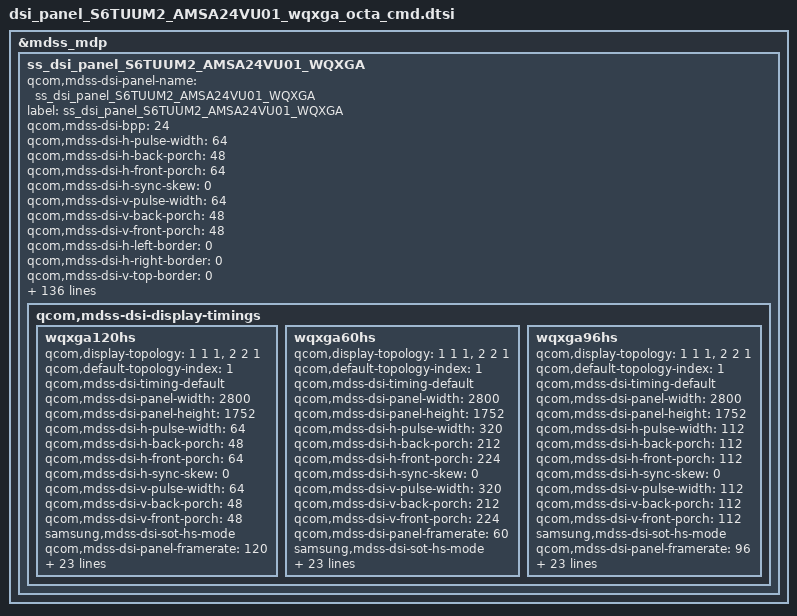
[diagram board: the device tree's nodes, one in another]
/* Copyright (c) 2012, Samsung Electronics Corporation. All rights reserved.
 *
 * This program is free software; you can redistribute it and/or modify
 * it under the terms of the GNU General Public License version 2 and
 * only version 2 as published by the Free Software Foundation.
 *
 * This program is distributed in the hope that it will be useful,
 * but WITHOUT ANY WARRANTY; without even the implied warranty of
 * MERCHANTABILITY or FITNESS FOR A PARTICULAR PURPOSE.  See the
 * GNU General Public License for more details.
 */

&mdss_mdp {
	ss_dsi_panel_S6TUUM2_AMSA24VU01_WQXGA: ss_dsi_panel_S6TUUM2_AMSA24VU01_WQXGA {
		qcom,mdss-dsi-panel-name = "ss_dsi_panel_S6TUUM2_AMSA24VU01_WQXGA";
		label = "ss_dsi_panel_S6TUUM2_AMSA24VU01_WQXGA";

		qcom,mdss-dsi-bpp = <24>;

		/*qcom,cmd-sync-wait-broadcast;*/

		/* 120Hz */
		qcom,mdss-dsi-h-pulse-width = < 64>;
		qcom,mdss-dsi-h-back-porch = <48>;
		qcom,mdss-dsi-h-front-porch = <64>;
		qcom,mdss-dsi-h-sync-skew = <0>;

		qcom,mdss-dsi-v-pulse-width = <64>;
		qcom,mdss-dsi-v-back-porch = <48>;
		qcom,mdss-dsi-v-front-porch = <48>;

		qcom,mdss-dsi-h-left-border = <0>;
		qcom,mdss-dsi-h-right-border = <0>;
		qcom,mdss-dsi-v-top-border = <0>;
		qcom,mdss-dsi-v-bottom-border = <0>;

		qcom,mdss-dsi-underflow-color = <0xFF>;
		qcom,mdss-dsi-border-color = <0>;

		qcom,mdss-dsi-panel-framerate = <120>;
		//qcom,mdss-dsi-panel-clockrate = <1530000000>;
		qcom,mdss-dsi-panel-phy-timings = [00 31 0D 0D 2B 27 0D 0D 09 02 04 00 27 1C];
		qcom,mdss-dsi-t-clk-pre = <0x27>;
		qcom,mdss-dsi-t-clk-post = <0x1C>;

		qcom,mdss-dsi-bl-pmic-control-type = "bl_ctrl_dcs";

		qcom,mdss-dsi-bl-min-level = <1>;
		qcom,mdss-dsi-bl-max-level = <355>;
		qcom,mdss-brightness-max-level = <355>;
		qcom,mdss-brightness-default-level = <255>;
		qcom,mdss-dsi-interleave-mode = <0>;
		qcom,mdss-dsi-panel-type = "dsi_cmd_mode";

		qcom,mdss-dsi-te-check-enable;
		qcom,mdss-dsi-te-using-te-pin;
		qcom,mdss-dsi-te-pin-select = <1>;

		/*qcom,dynamic-mode-switch-enabled;*/
		/*qcom,dynamic-mode-switch-type = "dynamic-resolution-switch-immediate";*/

		qcom,mdss-dsi-te-dcs-command = <1>;
		qcom,mdss-dsi-wr-mem-start = <0x2C>;
		qcom,mdss-dsi-wr-mem-continue = <0x3C>;

		qcom,mdss-dsi-pixel-packing = "loose";

		qcom,mdss-dsi-virtual-channel-id = <0>;
		qcom,mdss-dsi-color-order = "rgb_swap_rgb";
		qcom,mdss-dsi-lane-0-state;
		qcom,mdss-dsi-lane-1-state;
		qcom,mdss-dsi-lane-2-state;
		qcom,mdss-dsi-lane-3-state;
		qcom,mdss-dsi-lane-map = "lane_map_0123";
		samsung,num_of_data_lanes = <4>;

		qcom,mdss-dsi-stream = <0>;
		qcom,mdss-dsi-mdp-trigger = "none";
		qcom,mdss-dsi-dma-trigger = "trigger_sw";

		qcom,mdss-pan-physical-width-dimension = <272>; /* 272.82, round off */
		qcom,mdss-pan-physical-height-dimension = <175>; /* 175.0608, round off */

		qcom,mdss-dsi-reset-sequence = <0 1>, <1 1>;

		/*qcom,mdss-dsi-lp11-init;*/
		/*qcom,mdss-dsi-init-delay-us = <1000>;*/
		/*samsung,mdss-dsi-off-reset-delay-us = <1000>;*/

		qcom,mdss-dsi-rx-eot-ignore;
		qcom,mdss-dsi-tx-eot-append;

		/* HDR Setting */
		qcom,mdss-dsi-panel-hdr-enabled;
		qcom,mdss-dsi-panel-hdr-color-primaries = <15635 16450 34000 16000 13250 34500 7500 3000>;
		qcom,mdss-dsi-panel-peak-brightness = <5400000>;
		qcom,mdss-dsi-panel-average-brightness = <2000000>;
		qcom,mdss-dsi-panel-blackness-level = <2000>;

		qcom,ulps-enabled;
		/* qcom,suspend-ulps-enabled; */
		qcom,esd-check-enabled;
		qcom,mdss-dsi-panel-status-check-mode ="irq_check";
		/*qcom,mdss-dsi-panel-status-read-length;*/
		/*qcom,mdss-dsi-panel-status-value;*/
		/*qcom,mdss-dsi-panel-status-irq-trigger1 = "rising";*/
		qcom,mdss-dsi-panel-status-irq-trigger1 = "falling";

		/* *************************************************************
		 * Below  parameters are samsung dependent thigs
		 * *************************************************************
		 */
		samsung,panel-vendor = "SDC";
		samsung,disp-model = "AMSA24VU01";
		/*samsung,tcon-clk-on-support;*/ /* Enable only if HS clock is needed always like ANA */
		samsung,anapass-power-seq;
		samsung,delay-after-tcon-ready = <50>;  //PV1:100ms, PV2:50ms
		//samsung,panel-lpm-enable;
		samsung,esc-clk-128M;
		samsung,support_gamma_mode2;
		//samsung,elvss_interpolation_temperature = <(-15)>;
		//samsung,support_factory_panel_swap;
		//samsung,support_gct;
		//samsung,support_pac;
		//samsung,support_gpara; 2byte G-para
		// samsung,support_poc_driver;
		samsung,support_dynamic_mipi_clk;
		samsung,pll_ssc_disabled;
		samsung,no_qcom_pps;

		samsung,support-optical-fingerprint;
		samsung,not-support-single-tx; /* Do not support single tx */

		/* *************************************************************
		 *  Tx
		 * *************************************************************
		 */
		//samsung,level0_key_enable_tx_cmds_revA	= [29 01 00 00 00 00 03 9F A5 A5]; /* PASSWD0 */
		//samsung,level0_key_disable_tx_cmds_revA	= [29 01 00 00 00 00 03 9F 5A 5A]; /* PASSWD0 */
		//samsung,level1_key_enable_tx_cmds_revA	= [29 01 00 00 00 00 03 F0 5A 5A]; /* PASSWD1 */
		//samsung,level1_key_disable_tx_cmds_revA	= [29 01 00 00 00 00 03 F0 A5 A5]; /* PASSWD1 */
		//samsung,level2_key_enable_tx_cmds_revA	= [29 01 00 00 00 00 03 FC 5A 5A];
		//samsung,level2_key_disable_tx_cmds_revA	= [29 01 00 00 00 00 03 FC A5 A5];

		/* BRIGHTNESS_MAX_PACKET = 50 */
		samsung,brightness_tx_cmds_revA = [
			39 01 00 00 00 00 01 00
			39 01 00 00 00 00 01 00
			39 01 00 00 00 00 01 00
			39 01 00 00 00 00 01 00
			39 01 00 00 00 00 01 00
			39 01 00 00 00 00 01 00
			39 01 00 00 00 00 01 00
			39 01 00 00 00 00 01 00
			39 01 00 00 00 00 01 00
			39 01 00 00 00 00 01 00
			39 01 00 00 00 00 01 00
			39 01 00 00 00 00 01 00
			39 01 00 00 00 00 01 00
			39 01 00 00 00 00 01 00
			39 01 00 00 00 00 01 00
			39 01 00 00 00 00 01 00
			39 01 00 00 00 00 01 00
			39 01 00 00 00 00 01 00
			39 01 00 00 00 00 01 00
			39 01 00 00 00 00 01 00
			39 01 00 00 00 00 01 00
			39 01 00 00 00 00 01 00
			39 01 00 00 00 00 01 00
			39 01 00 00 00 00 01 00
			39 01 00 00 00 00 01 00
			39 01 00 00 00 00 01 00
			39 01 00 00 00 00 01 00
			39 01 00 00 00 00 01 00
			39 01 00 00 00 00 01 00
			39 01 00 00 00 00 01 00
			39 01 00 00 00 00 01 00
			39 01 00 00 00 00 01 00
			39 01 00 00 00 00 01 00
			39 01 00 00 00 00 01 00
			39 01 00 00 00 00 01 00
			39 01 00 00 00 00 01 00
			39 01 00 00 00 00 01 00
			39 01 00 00 00 00 01 00
			39 01 00 00 00 00 01 00
			39 01 00 00 00 00 01 00
			39 01 00 00 00 00 01 00
			39 01 00 00 00 00 01 00
			39 01 00 00 00 00 01 00
			39 01 00 00 00 00 01 00
			39 01 00 00 00 00 01 00
			39 01 00 00 00 00 01 00
			39 01 00 00 00 00 01 00
			39 01 00 00 00 00 01 00
			39 01 00 00 00 00 01 00
			39 01 00 00 00 00 01 00
		];

		//samsung,mdnie_tx_cmds_revA = [
		//	39 01 00 00 00 00 00 00 00
		//];

		//samsung,packet_size_tx_cmds_revA = [
		//7 01 00 00 00 00 02 07 00
		//];

		samsung,reg_read_pos_tx_cmds_revA = [
			39 00 00 00 00 03 B0 00 00
		];

		//samsung,manufacture_read_pre_tx_cmds_revA = [
		//	05 01 00 00 14 00 02 11 00			/* Sleep out, wait 20ms(0x14) */
		//];

		samsung,display_on_tx_cmds_revA = [
			05 01 00 00 00 00 01 29
		];

		samsung,first_display_on_tx_cmds_revA = [
			39 01 00 00 00 00 05 F8 58 00 d0 1d
			39 01 00 00 00 00 05 F9 00 00 00 00
		];

		samsung,display_off_tx_cmds_revA = [
			05 01 00 00 00 00 01 28
			05 01 00 00 64 00 01 10
		];

		/* *************************************************************
		 *  Rx (Module Information READ)
		 * *************************************************************
		 */
		samsung,module_info_rx_cmds_revA = [06 01 00 00 00 00 01 A1 0B 00]; /* White color position, Mdnie */

		samsung,mdnie_read_rx_cmds_revA		= [06 01 00 00 00 00 01 A1 04 00]; /* White color position */
		samsung,manufacture_date_rx_cmds_revA	= [06 01 00 00 00 00 01 A1 04 04]; /* manufacture data 4 byte*/
		samsung,octa_id_rx_cmds_revA		= [06 01 00 00 00 00 01 A1 14 0B]; /* manufacture information */
		samsung,cell_id_rx_cmds_revA		= [06 01 00 00 00 00 01 A1 07 04]; /* manufacture data 7 byte*/
		samsung,ddi_id_rx_cmds_revA		= [06 01 00 00 00 00 01 d6 05 00]; /* CHIP ID : read D6 1~5th */

		samsung,manufacture_id0_rx_cmds_revA	= [06 01 00 00 00 00 01 da 01 00];
		samsung,manufacture_id1_rx_cmds_revA	= [06 01 00 00 00 00 01 db 01 00];
		samsung,manufacture_id2_rx_cmds_revA	= [06 01 00 00 00 00 01 dc 01 00];

		//samsung,smart_dimming_mtp_rx_cmds_revA	= [06 01 00 00 00 00 01 c8 20 00];

		samsung,ldi_debug0_rx_cmds_revA		= [06 01 00 00 00 00 01 0A 01 00]; /* rddpm */
		samsung,ldi_debug1_rx_cmds_revA		= [06 01 00 00 00 00 01 B1 01 00]; /* TabS7+: flash done */
		samsung,ldi_debug2_rx_cmds_revA		= [06 01 00 00 00 00 01 0E 01 00]; /* errfg */
		samsung,ldi_debug3_rx_cmds_revA		= [06 01 00 00 00 00 01 0E 01 00]; /* rddsm*/
		samsung,ldi_debug4_rx_cmds_revA		= [06 01 00 00 00 00 01 05 01 00]; /* dsierr */
		//samsung,ldi_debug5_rx_cmds_revA		= [06 01 00 00 00 00 01 df 7C 00]; /* self_diag*/

		/* 255 bytes, its ddi max size is 512, and sw limit is ff = 255... */
		//samsung,ldi_debug_logbuf_rx_cmds_revA	= [06 01 00 00 00 00 01 9C FF 00];
		samsung,ddi_fw_id_rx_cmds_revA	= [06 01 00 00 00 00 01 F7 04 00];

		samsung,mtp_read_sysfs_rx_cmds_revA	= [06 01 00 00 00 00 01 00 00 00];
		samsung,mtp_write_sysfs_tx_cmds_revA	= [
			39 00 00 00 00 00 3D 00
						00 00 00 00 00 00 00 00 00 00
						00 00 00 00 00 00 00 00 00 00
						00 00 00 00 00 00 00 00 00 00
						00 00 00 00 00 00 00 00 00 00
						00 00 00 00 00 00 00 00 00 00
						00 00 00 00 00 00 00 00 00 00
		];

		/* *************************************************************
		 *  SELF DISPLAY
		 * *************************************************************
		 */
		samsung,support_self_display;
		ss,self_display = <&self_display_UM1_dtsi>;

		/* *************************************************************
		 * TEST MODE
		 * **************************************************************
		 */

		/* DIA */
		//samsung,dia_on_tx_cmds_revA = [
		//	05 01 00 00 32 00 01 15
		//];

		//samsung,dia_off_tx_cmds_revA = [
		//	39 01 00 00 00 00 0B F0 00 00 00 00 02 00 00 00 12 34
		//];

#if 0
		/* MCD TEST */
		samsung,mcd_on_tx_cmds_revA = [
					05 01 00 00 00 00 02 15 00
					39 01 00 00 00 00 0B F0 00 00 00 00 02 00 00 00 11 22
		];

		samsung,mcd_off_tx_cmds_revA = [
					05 01 00 00 00 00 02 15 00
					39 01 00 00 00 00 0B F0 00 00 00 00 02 00 00 00 55 66
		];
#endif

		/* *************************************************************
		 * ACL command list and mappings
		 * **************************************************************
		 */
		samsung,acl_on_tx_cmds_revA = [
			/* 32 frame AVG ACL ON, Start 50%, ACL 15%, 32Frame AVG */
			39 01 00 00 00 00 02 55 02	/* 55h 15%:02, 8%:01, off:00 */
			39 01 00 00 00 00 03 B0 00 0F
			39 01 00 00 00 00 02 B8 55 /* 32frame avg:55, 16frame:44 */
			39 01 00 00 00 00 03 B0 00 11
			39 01 00 00 00 00 02 B8 7F /* start ponit 60%:99, 50%:7F */
		];

		samsung,acl_off_tx_cmds_revA = [
			/* 16 Frame AVG ACL OFF, Start Point 60%, ACL 0%*/
			39 01 00 00 00 00 02 55 00	/* ACL OFF */
		];

		/* *************************************************************
		 *  IRC
		 * **************************************************************
		 */
		samsung,support_irc;
		samsung,irc_tx_cmds_revA = [
			39 01 00 00 00 00 03 86 0A 6B	/* IRC ON, Moderato */
		];
		samsung,irc_off_tx_cmds_revA = [
			39 01 00 00 00 00 02 86 00	/* IRC OFF */
		];

		/* ************************************************************************************************************************
		* ELVSS command list and mappings
		* ************************************************************************************************************************
		*/
		//samsung,elvss_rx_cmds_revA = [ 06 01 00 00 00 00 01 B5 02 16];

		samsung,elvss_tx_cmds_revA = [
			39 01 00 00 00 00 03 B0 00 28
			39 01 00 00 00 00 07 68 E0 00 0C C1 1A 1A	/* elvss offset */
			39 01 00 00 00 00 02 68 14		/* temprature20:0x14 */
			39 01 00 00 00 00 03 B0 00 C3
			39 01 00 00 00 00 02 B3 0C	/* Compensation ON */
		];


		/* *************************************************************
		 * candela to index mappings
		 * **************************************************************
		 */
		samsung,candela_map_table_revA = < /* THIS TABLE USED FOR DIMMING */
		/* <idx> <from> <till> <gm2_wrdisbv> <cd> */
			0	0	0	10	2
			1	1	1	17	3
			2	2	2	24	5
			3	3	3	31	6
			4	4	4	38	8
			5	5	5	44	9
			6	6	6	51	10
			7	7	7	58	12
			8	8	8	65	13
			9	9	9	72	15
			10	10	10	79	16
			11	11	11	86	18
			12	12	12	93	19
			13	13	13	100	21
			14	14	14	106	22
			15	15	15	113	23
			16	16	16	120	25
			17	17	17	127	26
			18	18	18	134	27
			19	19	19	141	29
			20	20	20	148	30
			21	21	21	155	32
			22	22	22	162	33
			23	23	23	168	34
			24	24	24	175	36
			25	25	25	182	37
			26	26	26	189	39
			27	27	27	196	40
			28	28	28	203	42
			29	29	29	210	43
			30	30	30	217	45
			31	31	31	224	46
			32	32	32	230	47
			33	33	33	237	49
			34	34	34	244	50
			35	35	35	251	51
			36	36	36	258	53
			37	37	37	265	54
			38	38	38	272	56
			39	39	39	279	57
			40	40	40	286	59
			41	41	41	292	60
			42	42	42	299	61
			43	43	43	306	63
			44	44	44	313	64
			45	45	45	320	66
			46	46	46	327	67
			47	47	47	334	69
			48	48	48	341	70
			49	49	49	348	71
			50	50	50	355	73
			51	51	51	361	74
			52	52	52	368	76
			53	53	53	375	77
			54	54	54	382	78
			55	55	55	389	80
			56	56	56	396	81
			57	57	57	403	83
			58	58	58	410	84
			59	59	59	417	86
			60	60	60	423	87
			61	61	61	430	88
			62	62	62	437	90
			63	63	63	444	91
			64	64	64	451	93
			65	65	65	458	94
			66	66	66	465	95
			67	67	67	472	97
			68	68	68	479	98
			69	69	69	485	100
			70	70	70	492	101
			71	71	71	499	102
			72	72	72	506	104
			73	73	73	513	105
			74	74	74	520	107
			75	75	75	527	108
			76	76	76	534	110
			77	77	77	541	111
			78	78	78	547	112
			79	79	79	554	114
			80	80	80	561	115
			81	81	81	568	117
			82	82	82	575	118
			83	83	83	582	119
			84	84	84	589	121
			85	85	85	596	122
			86	86	86	603	124
			87	87	87	609	125
			88	88	88	616	126
			89	89	89	623	128
			90	90	90	630	129
			91	91	91	637	131
			92	92	92	644	132
			93	93	93	651	134
			94	94	94	658	135
			95	95	95	665	136
			96	96	96	671	138
			97	97	97	678	139
			98	98	98	685	141
			99	99	99	692	142
			100	100	100	699	143
			101	101	101	706	145
			102	102	102	713	146
			103	103	103	720	148
			104	104	104	727	149
			105	105	105	733	150
			106	106	106	740	152
			107	107	107	747	153
			108	108	108	754	155
			109	109	109	761	156
			110	110	110	768	158
			111	111	111	775	159
			112	112	112	782	160
			113	113	113	789	162
			114	114	114	796	163
			115	115	115	802	165
			116	116	116	809	166
			117	117	117	816	167
			118	118	118	823	169
			119	119	119	830	170
			120	120	120	837	172
			121	121	121	844	173
			122	122	122	851	175
			123	123	123	858	176
			124	124	124	864	177
			125	125	125	871	179
			126	126	126	878	180
			127	127	127	885	182
			128	128	128	892	183
			129	129	129	901	185
			130	130	130	910	187
			131	131	131	919	189
			132	132	132	928	190
			133	133	133	937	192
			134	134	134	947	194
			135	135	135	956	196
			136	136	136	965	198
			137	137	137	974	200
			138	138	138	983	202
			139	139	139	992	204
			140	140	140	1001	205
			141	141	141	1010	207
			142	142	142	1019	209
			143	143	143	1028	211
			144	144	144	1038	213
			145	145	145	1047	215
			146	146	146	1056	217
			147	147	147	1065	219
			148	148	148	1074	220
			149	149	149	1083	222
			150	150	150	1092	224
			151	151	151	1101	226
			152	152	152	1110	228
			153	153	153	1119	230
			154	154	154	1128	231
			155	155	155	1138	233
			156	156	156	1147	235
			157	157	157	1156	237
			158	158	158	1165	239
			159	159	159	1174	241
			160	160	160	1183	243
			161	161	161	1192	245
			162	162	162	1201	246
			163	163	163	1210	248
			164	164	164	1219	250
			165	165	165	1228	252
			166	166	166	1238	254
			167	167	167	1247	256
			168	168	168	1256	258
			169	169	169	1265	260
			170	170	170	1274	261
			171	171	171	1283	263
			172	172	172	1292	265
			173	173	173	1301	267
			174	174	174	1310	269
			175	175	175	1319	271
			176	176	176	1329	273
			177	177	177	1338	275
			178	178	178	1347	276
			179	179	179	1356	278
			180	180	180	1365	280
			181	181	181	1374	282
			182	182	182	1383	284
			183	183	183	1392	286
			184	184	184	1401	287
			185	185	185	1410	289
			186	186	186	1419	291
			187	187	187	1429	293
			188	188	188	1438	295
			189	189	189	1447	297
			190	190	190	1456	299
			191	191	191	1465	301
			192	192	192	1474	302
			193	193	193	1483	304
			194	194	194	1492	306
			195	195	195	1501	308
			196	196	196	1510	310
			197	197	197	1520	312
			198	198	198	1529	314
			199	199	199	1538	316
			200	200	200	1547	317
			201	201	201	1556	319
			202	202	202	1565	321
			203	203	203	1574	323
			204	204	204	1583	325
			205	205	205	1592	327
			206	206	206	1601	328
			207	207	207	1610	330
			208	208	208	1620	332
			209	209	209	1629	334
			210	210	210	1638	336
			211	211	211	1647	338
			212	212	212	1656	340
			213	213	213	1665	342
			214	214	214	1674	343
			215	215	215	1683	345
			216	216	216	1692	347
			217	217	217	1701	349
			218	218	218	1711	351
			219	219	219	1720	353
			220	220	220	1729	355
			221	221	221	1738	357
			222	222	222	1747	358
			223	223	223	1756	360
			224	224	224	1765	362
			225	225	225	1774	364
			226	226	226	1783	366
			227	227	227	1792	368
			228	228	228	1801	370
			229	229	229	1811	372
			230	230	230	1820	373
			231	231	231	1829	375
			232	232	232	1838	377
			233	233	233	1847	379
			234	234	234	1856	381
			235	235	235	1865	383
			236	236	236	1874	385
			237	237	237	1883	386
			238	238	238	1892	388
			239	239	239	1901	390
			240	240	240	1911	392
			241	241	241	1920	394
			242	242	242	1929	396
			243	243	243	1938	397
			244	244	244	1947	399
			245	245	245	1956	401
			246	246	246	1965	403
			247	247	247	1974	405
			248	248	248	1983	407
			249	249	249	1992	409
			250	250	250	2002	411
			251	251	251	2011	413
			252	252	252	2020	414
			253	253	253	2029	416
			254	254	254	2038	418
			255	255	255	2047	420
		>;
		samsung,hbm_candela_map_table_revA = < /* THIS TABLE USED FOR DIMMING */
		/* <idx> <from> <till> <gm2_wrdisbv> <cd> <auto> */
			0	256	257	338	424	0
			1	258	260	324	428	0
			2	261	262	311	432	0
			3	263	265	295	436	0
			4	266	267	280	440	0
			5	268	270	265	444	0
			6	271	272	250	448	0
			7	273	274	235	452	0
			8	275	277	218	456	0
			9	278	279	200	460	0
			10	280	282	187	464	0
			11	283	284	169	468	0
			12	285	287	150	472	0
			13	288	289	135	476	0
			14	290	291	112	480	0
			15	292	294	97	484	0
			16	295	296	77	488	0
			17	297	299	60	492	0
			18	300	301	40	496	0
			19	302	304	20	500	0
		>;

		samsung,gamma_mode2_normal_tx_cmds_revA=[
			39 01 00 00 00 00 02 53 20
			39 01 00 00 00 00 05 68 19 20 00 14
			39 01 00 00 00 00 03 51 D8 0D
		];

		/* 120hz hbm gamma2 */
		samsung,gamma_mode2_hbm_tx_cmds_revA=[
			39 01 00 00 00 00 02 53 E0
			39 01 00 00 00 00 03 B0 00 79
			39 01 00 00 00 00 03 C7 01 54
			39 01 00 00 00 00 03 B0 00 79
			39 01 00 00 00 00 03 C7 01 54
		];

		//samsung,gamma_mode2_hbm_60hz_tx_cmds_revA=[
		//	39 01 00 00 00 00 02 53 E0
		//	39 01 00 00 00 00 05 B8 80 00 01 52
		//];

		/* *************************************************************
		 *  VRR
		 * **************************************************************
		 */
		samsung,vrr_tx_cmds_revA = [
					/* Freq Setting: 120*/
					39 01 00 00 00 00 03 B0 00 BC
					39 01 00 00 00 00 03 CB 02 00
					39 01 00 00 00 00 03 B0 00 C0
					39 01 00 00 14 00 03 CB 03 00
					39 01 00 00 00 00 02 60 20
		];

		samsung,rsc_4_frame_idle;

		samsung,support_vrr_based_bl; /* VRR Variable Refresh Rate */

		/* *************************************************************
		 * Dynamic MIPI Clock
		 * **************************************************************
		 */
#if 0
		samsung,ffc_tx_cmds_revA = [
			29 00 00 00 00 00 03 FC 5A 5A		/* TEST KEY3 Enable*/
			29 00 00 00 00 00 06 C5 09 30 0E 26 BE	/* default: 897.6 Mbps */
			29 00 00 00 00 00 03 FC A5 A5		/* TEST KEY3 Disable*/
		];

	        samsung,dyn_mipi_clk_ffc_cmds_revA = [
	            29 00 00 00 00 00 08 C5 0D 00 C8 29 0F 29 0F    /* 0. Default 1362 Mbps */
	            29 00 00 00 00 00 08 C5 0D 00 C8 2A 1C 2A 1C    /* 1. 1328 Mbps */
	            29 00 00 00 00 00 08 C5 0D 00 C8 29 0F 29 0F    /* 2. 1362 Mbps */
	            29 00 00 00 00 00 08 C5 0D 00 C8 28 E1 28 E1    /* 3. 1368 Mbps */
	            29 00 00 00 00 00 08 C5 0D 00 C8 28 E1 28 E1    /* 4. 1368 Mbps */
	        ];
#endif
	        samsung,dynamic_mipi_clk_timing_table = <
	            /*<bitclk><>*/
	            1500000000 /* clk id 0 default */
	            1508000000 /* clk id 1  */
	            1530000000 /* clk id 2 */
	            1531000000 /* clk id 3 */
	            1550000000 /* clk id 4 */
	        >;

		samsung,dynamic_mipi_clk_sel_table = <
			/*<RAT><BAND><from><end><clk index>*/
				1	1	0	0	1
				1	2	0	0	4
				1	3	0	0	2
				1	4	0	0	3
				2	11	10562	10646	1
				2	11	10647	10716	2
				2	11	10717	10838	1
				2	12	9662	9704	1
				2	12	9705	9774	2
				2	12	9775	9938	1
				2	13	1162	1200	1
				2	13	1201	1270	2
				2	13	1271	1513	1
				2	14	1537	1621	1
				2	14	1622	1691	2
				2	14	1692	1738	1
				2	15	4357	4363	1
				2	15	4364	4427	2
				2	15	4428	4430	3
				2	15	4431	4433	4
				2	15	4434	4458	1
				2	17	2237	2284	1
				2	17	2285	2354	2
				2	17	2355	2563	1
				2	18	2937	2977	1
				2	18	2978	3046	2
				2	18	3047	3047	3
				2	18	3048	3088	1
				3	91	0	193	1
				3	91	194	333	2
				3	91	334	599	1
				3	92	600	708	1
				3	92	709	848	2
				3	92	849	1199	1
				3	93	1200	1301	1
				3	93	1302	1441	2
				3	93	1442	1929	1
				3	93	1930	1949	2
				3	94	1950	2143	1
				3	94	2144	2283	2
				3	94	2284	2399	1
				3	95	2400	2436	1
				3	95	2437	2564	2
				3	95	2565	2570	3
				3	95	2571	2576	4
				3	95	2577	2649	1
				3	97	2750	2869	1
				3	97	2870	3009	2
				3	97	3010	3449	1
				3	98	3450	3554	1
				3	98	3555	3692	2
				3	98	3693	3694	3
				3	98	3695	3799	1
				3	102	5010	5179	1
				3	103	5180	5189	1
				3	103	5190	5279	2
				3	104	5280	5284	3
				3	104	5285	5309	4
				3	104	5310	5379	1
				3	107	5730	5849	1
				3	108	5850	5976	1
				3	108	5977	5999	2
				3	109	6000	6104	2
				3	109	6105	6110	3
				3	109	6111	6116	4
				3	109	6117	6149	1
				3	110	6150	6338	1
				3	110	6339	6449	2
				3	111	6450	6500	1
				3	111	6501	6599	2
				3	115	8040	8148	1
				3	115	8149	8288	2
				3	115	8289	8689	1
				3	116	8690	8826	1
				3	116	8827	8954	2
				3	116	8955	8960	3
				3	116	8961	8966	4
				3	116	8967	9039	1
				3	118	9210	9214	3
				3	118	9215	9239	4
				3	118	9240	9659	1
				3	119	9660	9769	1
				3	120	9770	9869	1
				3	122	9920	9921	2
				3	122	9922	10359	1
				3	124	36200	36276	2
				3	124	36277	36349	1
				3	128	37750	37881	2
				3	128	37882	38249	1
				3	129	38250	38369	2
				3	129	38370	38649	1
				3	130	38650	38828	1
				3	130	38829	38968	2
				3	130	38969	39456	1
				3	130	39457	39596	2
				3	130	39597	39649	1
				3	131	39650	39753	1
				3	131	39754	39893	2
				3	131	39894	40381	1
				3	131	40382	40521	2
				3	131	40522	41009	1
				3	131	41010	41149	2
				3	131	41150	41589	1
				3	132	41590	42078	1
				3	132	42079	42085	4
				3	132	42086	42218	2
				3	132	42219	42706	1
				3	132	42707	42722	4
				3	132	42723	42846	2
				3	132	42847	43335	1
				3	132	43336	43360	4
				3	132	43361	43475	2
				3	132	43476	43589	1
				3	138	55240	55485	1
				3	138	55486	55510	4
				3	138	55511	55625	2
				3	138	55626	56113	1
				3	138	56114	56147	4
				3	138	56148	56253	2
				3	138	56254	56739	1
				3	156	66436	66629	1
				3	156	66630	66769	2
				3	156	66770	67257	1
				3	156	67258	67335	2
				3	161	68586	68629	1
				3	161	68630	68720	2
				3	161	68721	68725	3
				3	161	68726	68769	4
				3	161	68770	68935	1
				4	51	0	0	2
				4	52	0	0	3
				4	53	0	0	2
				4	54	0	0	2
				4	55	0	0	1
				4	56	0	0	4
				5	61	0	0	4
				5	62	0	0	1
				5	71	0	0	2
				7	260	173800	176080	2
				7	260	176081	176200	3
				7	260	176201	178320	4
				7	260	178321	178780	1
				7	263	185000	186080	1
				7	263	186081	188840	2
				7	263	188841	188960	3
				7	263	188961	190880	4
				7	263	190881	191980	1
				7	283	151600	152880	4
				7	283	152881	160580	1
				7	326	123400	125080	2
				7	326	125081	125180	3
				7	326	125181	127410	4
				7	326	127411	130380	1
		>;

		/*
		 * ************************************************************************************************************************
		 *  FD Settings
		 * ************************************************************************************************************************
		 */

		//samsung,fd_on_tx_cmds_revA = [
		//	29 01 00 00 00 00 03 F0 5A 5A
		//	29 01 00 00 00 00 03 B0 0B B5
		//	29 01 00 00 00 00 02 B5 40
		//	29 01 00 00 00 00 03 F0 A5 A5
		//];

		//samsung,fd_off_tx_cmds_revA = [
		//	29 01 00 00 00 00 03 F0 5A 5A
		//	29 01 00 00 00 00 03 B0 0B B5
		//	29 01 00 00 00 00 02 B5 80
		//	29 01 00 00 00 00 03 F0 A5 A5
		//];

		/*
		* ************************************************************************************************************************
		*  DMS (Dynamic Mode Switch)
		* ************************************************************************************************************************
		*/

		qcom,mdss-dsi-display-timings {
			wqxga120hs {
				qcom,display-topology = <1 1 1>, <2 2 1>;
				qcom,default-topology-index = <1>;
				qcom,mdss-dsi-timing-default;
				qcom,mdss-dsi-panel-width = <2800>;
				qcom,mdss-dsi-panel-height = <1752>;

				/* 120Hz */
				qcom,mdss-dsi-h-pulse-width = < 64>;
				qcom,mdss-dsi-h-back-porch = <48>;
				qcom,mdss-dsi-h-front-porch = <64>;
				qcom,mdss-dsi-h-sync-skew = <0>;

				qcom,mdss-dsi-v-pulse-width = <64>;
				qcom,mdss-dsi-v-back-porch = <48>;
				qcom,mdss-dsi-v-front-porch = <48>;

				samsung,mdss-dsi-sot-hs-mode;
				qcom,mdss-dsi-panel-framerate = <120>;
				qcom,mdss-mdp-transfer-time-us = <7533>;
				qcom,mdss-dsi-panel-clockrate = <1530000000>;
				qcom,mdss-dsi-panel-phy-timings = [00 31 0D 0D 2B 27 0D 0D 09 02 04 00 27 1C];
				qcom,mdss-dsi-t-clk-pre = <0x27>;
				qcom,mdss-dsi-t-clk-post = <0x1C>;

				/*qcom,mdss-dsi-timing-switch-command; use samsung,panel_multires_XXX instead*/
				/*qcom,mdss-dsi-timing-switch-command-state;*/

				qcom,mdss-dsi-timing-switch-command = [ /* This will not be used if not multi-resolution */
					/* Freq Setting: 120*/	/* So use this for vrr fps change */
					39 01 00 00 00 00 03 B0 00 BC
					39 01 00 00 00 00 03 CB 02 00
					39 01 00 00 00 00 03 B0 00 C0
					39 01 00 00 14 00 03 CB 03 00
					39 01 00 00 00 00 02 60 20
				];

				qcom,mdss-dsi-on-command = [
					/* DSC Compression Enable */
					07 01 00 00 00 00 01 01

					/* PPS Setting */
					39 01 00 00 00 00 59 9E
								11 01 00 89 30 80 06 D8 0A F0
								00 0C 05 78 05 78 	02 00 03 BD
								00 20 01 9C 00 13 00 0C 08 BB
								03 45 18 00 10 F0 03 0C 20 00
								06 0B 0B 33 0E 1C 2A 38 46 54
								62 69 70 77 79 7B 7D 7E 01 02
								01 00 09 40 09 BE 19 FC 19 FA
								19 F8 1A 38 1A 78 1A B6 2A F6
								2b 34 2b 74 3B 74 63 F4

					/* Dither */
					39 01 00 00 00 00 02 91 10
#if 0
					/* Freq Setting: 120*/
					39 01 00 00 00 00 03 B0 00 BC
					39 01 00 00 00 00 03 CB 02 00
					39 01 00 00 00 00 03 B0 00 C0
					39 01 00 00 14 00 03 CB 03 00
					39 01 00 00 00 00 02 60 20

					/* Brightness */
					39 01 00 00 00 00 02 53 28
					39 01 00 00 00 00 05 68 19 20 00 14
					39 01 00 00 00 00 03 51 FF 07
#endif
					/* ACL ON Normal*/
					39 01 00 00 00 00 02 55 02	/* 55h 15%:02, 8%:01, off:00 */
					39 01 00 00 00 00 03 B0 00 0F
					39 01 00 00 00 00 02 B8 55 /* 32frame avg:55, 16frame:44 */
					39 01 00 00 00 00 03 B0 00 11
					39 01 00 00 00 00 02 B8 7F /* start ponit 60%:99, 50%:7F */

					/* ELVSS ON */
					39 01 00 00 00 00 03 B0 00 28
					39 01 00 00 00 00 07 68 E0 00 0C C1 1A 1A	/* elvss offset */
					39 01 00 00 00 00 02 68 14		/* temprature25:0x19 */
					39 01 00 00 00 00 03 B0 00 C3
					39 01 00 00 00 00 02 B3 0C	/* Compensation ON */

					/* IRC ON */
					39 01 00 00 00 00 03 86 0A 6B	/* IRC ON, Moderato */

					/* samsung mcd ip, mdnie */
					39 01 00 00 00 00 03 B0 00 19
					39 01 00 00 00 00 08 C5 01 01 01 01 01 01 01
					/* 4C, 5C mcu access disable */
					39 01 00 00 00 00 03 B0 00 14
					39 01 00 00 00 00 03 D7 4C 5C

					/* ELP Setting */
					39 01 00 00 00 00 03 B0 00 08
					39 01 00 00 00 00 02 5D 00  /* off */
 				];

				qcom,mdss-dsi-off-command=[
					05 01 00 00 64 00 01 28
				];

				qcom,mdss-dsi-on-command-state = "dsi_hs_mode";
				qcom,mdss-dsi-off-command-state = "dsi_hs_mode";

			/*
				qcom,partial-update-enabled = "single_roi";
				qcom,panel-roi-alignment=<1400 12 1400 12 1400 12>;
			*/
				qcom,compression-mode = "dsc";
				qcom,lm-split = <1400 1400>;
				qcom,mdss-dsc-encoders = <2>;
				qcom,mdss-dsc-slice-height = <12>;
				qcom,mdss-dsc-slice-width = <1400>;
				qcom,mdss-dsc-slice-per-pkt = <1>;
				qcom,mdss-dsc-bit-per-component = <8>;
				qcom,mdss-dsc-bit-per-pixel = <8>;
				qcom,mdss-dsc-block-prediction-enable;
			};

			wqxga60hs {
				qcom,display-topology = <1 1 1>, <2 2 1>;
				qcom,default-topology-index = <1>;
				qcom,mdss-dsi-timing-default;
				qcom,mdss-dsi-panel-width = <2800>;
				qcom,mdss-dsi-panel-height = <1752>;

				qcom,mdss-dsi-h-pulse-width = <320>; /* 60hz*/
				qcom,mdss-dsi-h-back-porch = <212>;
				qcom,mdss-dsi-h-front-porch = <224>;
				qcom,mdss-dsi-h-sync-skew = <0>;

				qcom,mdss-dsi-v-pulse-width = <320>;
				qcom,mdss-dsi-v-back-porch = <212>;
				qcom,mdss-dsi-v-front-porch = <224>;

				qcom,mdss-dsi-panel-framerate = <60>;
				samsung,mdss-dsi-sot-hs-mode;
				qcom,mdss-mdp-transfer-time-us = <7533>;
				qcom,mdss-dsi-panel-clockrate = <1530000000>;
				qcom,mdss-dsi-panel-phy-timings = [00 31 0D 0D 2B 27 0D 0D 09 02 04 00 27 1C];
				qcom,mdss-dsi-t-clk-pre = <0x27>;
				qcom,mdss-dsi-t-clk-post = <0x1C>;

				/*qcom,mdss-dsi-timing-switch-command; use samsung,panel_multires_XXX instead*/
				/*qcom,mdss-dsi-timing-switch-command-state;*/
				qcom,mdss-dsi-timing-switch-command = [ /* This will not be used if not multi-resolution*/
					/* Freq Setting: 60*/
					39 01 00 00 14 00 02 60 00
					39 01 00 00 00 00 03 B0 00 C0
					39 01 00 00 00 00 03 CB F3 06
					39 01 00 00 00 00 03 B0 00 BC
					39 01 00 00 00 00 03 CB F2 06
				];
				qcom,mdss-dsi-on-command = [
					/* DSC Compression Enable */
					07 01 00 00 00 00 01 01

					/* PPS Setting */
					39 01 00 00 00 00 59 9E
								11 01 00 89 30 80 06 D8 0A F0
								00 0C 05 78 05 78 	02 00 03 BD
								00 20 01 9C 00 13 00 0C 08 BB
								03 45 18 00 10 F0 03 0C 20 00
								06 0B 0B 33 0E 1C 2A 38 46 54
								62 69 70 77 79 7B 7D 7E 01 02
								01 00 09 40 09 BE 19 FC 19 FA
								19 F8 1A 38 1A 78 1A B6 2A F6
								2b 34 2b 74 3B 74 63 F4

					/* Dither */
					39 01 00 00 00 00 02 91 10
#if 0
					/* Freq Setting: 60*/
					39 01 00 00 14 00 02 60 00
					39 01 00 00 00 00 03 B0 00 C0
					39 01 00 00 00 00 03 CB F3 06
					39 01 00 00 00 00 03 B0 00 BC
					39 01 00 00 00 00 03 CB F2 06

					/* Brightness */
					39 01 00 00 00 00 02 53 28
					39 01 00 00 00 00 05 68 19 20 00 14
					39 01 00 00 00 00 03 51 FF 07
#endif
					/* ACL ON Normal*/
					39 01 00 00 00 00 02 55 02	/* 55h 15%:02, 8%:01, off:00 */
					39 01 00 00 00 00 03 B0 00 0F
					39 01 00 00 00 00 02 B8 55 /* 32frame avg:55, 16frame:44 */
					39 01 00 00 00 00 03 B0 00 11
					39 01 00 00 00 00 02 B8 7F /* start ponit 60%:99, 50%:7F */

					/* ELVSS ON */
					39 01 00 00 00 00 03 B0 00 28
					39 01 00 00 00 00 07 68 E0 00 0C C1 1A 1A	/* elvss offset */
					39 01 00 00 00 00 02 68 14		/* temprature25:0x19 */
					39 01 00 00 00 00 03 B0 00 C3
					39 01 00 00 00 00 02 B3 0C	/* Compensation ON */

					/* IRC ON */
					39 01 00 00 00 00 03 86 0A 6B	/* IRC ON, Moderato */

					/* samsung mcd ip, mdnie */
					39 01 00 00 00 00 03 B0 00 19
					39 01 00 00 00 00 08 C5 01 01 01 01 01 01 01
					/* 4C, 5C mcu access disable */
					39 01 00 00 00 00 03 B0 00 14
					39 01 00 00 00 00 03 D7 4C 5C

					/* ELP Setting */
					39 01 00 00 00 00 03 B0 00 08
					39 01 00 00 00 00 02 5D 00  /* off */
				];

				qcom,mdss-dsi-off-command=[
					05 01 00 00 64 00 01 28
				];

				qcom,mdss-dsi-on-command-state = "dsi_hs_mode";
				qcom,mdss-dsi-off-command-state = "dsi_hs_mode";

			/*
				qcom,partial-update-enabled = "single_roi";
				qcom,panel-roi-alignment=<1400 12 1400 12 1400 12>;
			*/
				qcom,compression-mode = "dsc";
				qcom,lm-split = <1400 1400>;
				qcom,mdss-dsc-encoders = <2>;
				qcom,mdss-dsc-slice-height = <12>;
				qcom,mdss-dsc-slice-width = <1400>;
				qcom,mdss-dsc-slice-per-pkt = <1>;
				qcom,mdss-dsc-bit-per-component = <8>;
				qcom,mdss-dsc-bit-per-pixel = <8>;
				qcom,mdss-dsc-block-prediction-enable;
			};

			wqxga96hs {
				qcom,display-topology = <1 1 1>, <2 2 1>;
				qcom,default-topology-index = <1>;
				qcom,mdss-dsi-timing-default;
				qcom,mdss-dsi-panel-width = <2800>;
				qcom,mdss-dsi-panel-height = <1752>;

				/* 96Hz */
				qcom,mdss-dsi-h-pulse-width = < 112>;
				qcom,mdss-dsi-h-back-porch = <112>;
				qcom,mdss-dsi-h-front-porch = <112>;
				qcom,mdss-dsi-h-sync-skew = <0>;

				qcom,mdss-dsi-v-pulse-width = <112>;
				qcom,mdss-dsi-v-back-porch = <112>;
				qcom,mdss-dsi-v-front-porch = <112>;

				samsung,mdss-dsi-sot-hs-mode;
				qcom,mdss-dsi-panel-framerate = <96>;
				qcom,mdss-mdp-transfer-time-us = <7533>;
				qcom,mdss-dsi-panel-clockrate = <1530000000>;
				qcom,mdss-dsi-panel-phy-timings = [00 31 0D 0D 2B 27 0D 0D 09 02 04 00 27 1C];
				qcom,mdss-dsi-t-clk-pre = <0x27>;
				qcom,mdss-dsi-t-clk-post = <0x1C>;

				/*qcom,mdss-dsi-timing-switch-command; use samsung,panel_multires_XXX instead*/
				/*qcom,mdss-dsi-timing-switch-command-state;*/

				qcom,mdss-dsi-timing-switch-command = [ /* This will not be used if not multi-resolution */
					/* So use this for vrr fps change */
					/* Freq Setting: 96hz */
					39 01 00 00 00 00 03 B0 00 5D
					39 01 00 00 00 00 19 67
								08 AC 08 84 07 E3 07 19
								05 EA 03 F2 00 14 00 14
								00 14 00 14 00 14 00 14
					39 01 00 00 00 00 03 B0 00 04
					39 01 00 00 00 00 05 CF AB E8 2A 04
					39 01 00 00 00 00 03 B0 00 0C
					39 01 00 00 00 00 05 CF AC 08 2B 04
					39 01 00 00 00 00 03 B0 00 90
					39 01 00 00 00 00 03 D6 D0 01
					39 01 00 00 00 00 03 B0 00 BC
					39 01 00 00 00 00 03 CB 02 00
					39 01 00 00 00 00 03 B0 00 C0
					39 01 00 00 14 00 03 CB 03 00
					39 01 00 00 00 00 02 60 20
				];

				qcom,mdss-dsi-on-command = [
					/* DSC Compression Enable */
					07 01 00 00 00 00 01 01

					/* PPS Setting */
					39 01 00 00 00 00 59 9E
								11 01 00 89 30 80 06 D8 0A F0
								00 0C 05 78 05 78 	02 00 03 BD
								00 20 01 9C 00 13 00 0C 08 BB
								03 45 18 00 10 F0 03 0C 20 00
								06 0B 0B 33 0E 1C 2A 38 46 54
								62 69 70 77 79 7B 7D 7E 01 02
								01 00 09 40 09 BE 19 FC 19 FA
								19 F8 1A 38 1A 78 1A B6 2A F6
								2b 34 2b 74 3B 74 63 F4

					/* Dither */
					39 01 00 00 00 00 02 91 10
#if 0
					/* Freq Setting: 96hz */
					39 01 00 00 00 00 03 B0 00 5D
					39 01 00 00 00 00 19 67
								08 AC 08 84 07 E3 07 19
								05 EA 03 F2 00 14 00 14
								00 14 00 14 00 14 00 14
					39 01 00 00 00 00 03 B0 00 04
					39 01 00 00 00 00 05 CF AB E8 2A 04
					39 01 00 00 00 00 03 B0 00 0C
					39 01 00 00 00 00 05 CF AC 08 2B 04
					39 01 00 00 00 00 03 B0 00 90
					39 01 00 00 00 00 03 D6 D0 01
					39 01 00 00 00 00 03 B0 00 BC
					39 01 00 00 00 00 03 CB 02 00
					39 01 00 00 00 00 03 B0 00 C0
					39 01 00 00 14 00 03 CB 03 00
					39 01 00 00 00 00 02 60 20

					/* Brightness */
					39 01 00 00 00 00 02 53 28
					39 01 00 00 00 00 05 68 19 20 00 14
					39 01 00 00 00 00 03 51 FF 07
#endif
					/* ACL ON Normal*/
					39 01 00 00 00 00 02 55 02	/* 55h 15%:02, 8%:01, off:00 */
					39 01 00 00 00 00 03 B0 00 0F
					39 01 00 00 00 00 02 B8 55 /* 32frame avg:55, 16frame:44 */
					39 01 00 00 00 00 03 B0 00 11
					39 01 00 00 00 00 02 B8 7F /* start ponit 60%:99, 50%:7F */

					/* ELVSS ON */
					39 01 00 00 00 00 03 B0 00 28
					39 01 00 00 00 00 07 68 E0 00 0C C1 1A 1A	/* elvss offset */
					39 01 00 00 00 00 02 68 14		/* temprature25:0x19 */
					39 01 00 00 00 00 03 B0 00 C3
					39 01 00 00 00 00 02 B3 0C	/* Compensation ON */

					/* IRC ON */
					39 01 00 00 00 00 03 86 0A 6B	/* IRC ON, Moderato */

					/* samsung mcd ip, mdnie */
					39 01 00 00 00 00 03 B0 00 19
					39 01 00 00 00 00 08 C5 01 01 01 01 01 01 01
					/* 4C, 5C mcu access disable */
					39 01 00 00 00 00 03 B0 00 14
					39 01 00 00 00 00 03 D7 4C 5C

					/* ELP Setting */
					39 01 00 00 00 00 03 B0 00 08
					39 01 00 00 00 00 02 5D 00  /* off */
				];

				qcom,mdss-dsi-off-command=[
					05 01 00 00 64 00 01 28
				];

				qcom,mdss-dsi-on-command-state = "dsi_hs_mode";
				qcom,mdss-dsi-off-command-state = "dsi_hs_mode";

			/*
				qcom,partial-update-enabled = "single_roi";
				qcom,panel-roi-alignment=<1400 12 1400 12 1400 12>;
			*/
				qcom,compression-mode = "dsc";
				qcom,lm-split = <1400 1400>;
				qcom,mdss-dsc-encoders = <2>;
				qcom,mdss-dsc-slice-height = <12>;
				qcom,mdss-dsc-slice-width = <1400>;
				qcom,mdss-dsc-slice-per-pkt = <1>;
				qcom,mdss-dsc-bit-per-component = <8>;
				qcom,mdss-dsc-bit-per-pixel = <8>;
				qcom,mdss-dsc-block-prediction-enable;
			};
		};
	};
};
